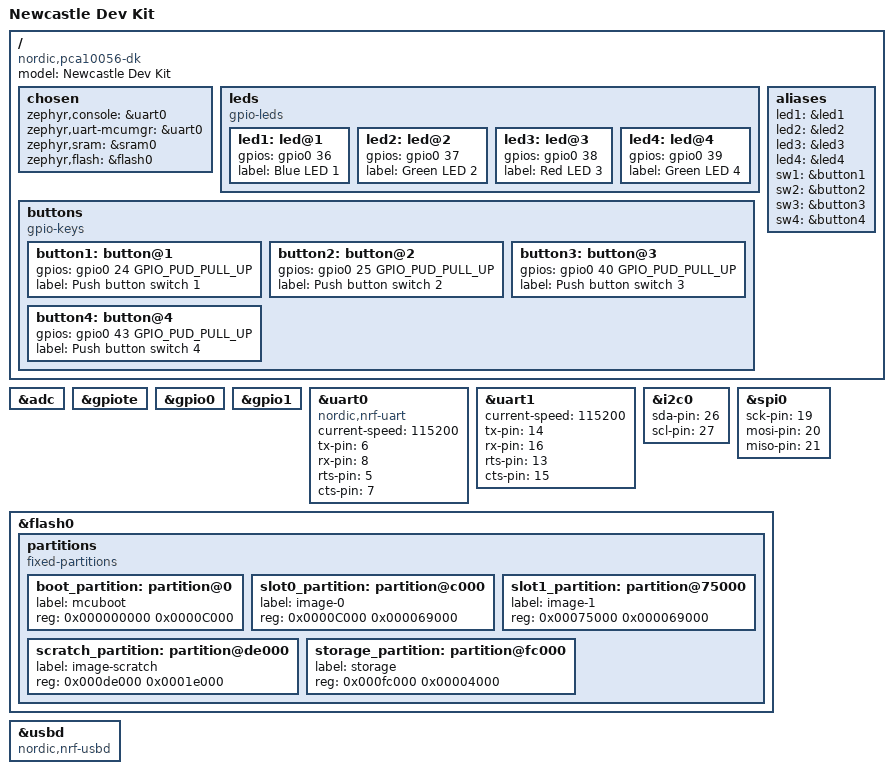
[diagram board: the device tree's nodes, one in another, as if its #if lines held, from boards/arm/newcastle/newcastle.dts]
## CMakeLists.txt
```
cmake_minimum_required(VERSION 3.8.2)
set(BOARD_ROOT ${CMAKE_CURRENT_LIST_DIR})
set(BOARD newcastle)
include($ENV{ZEPHYR_BASE}/cmake/app/boilerplate.cmake NO_POLICY_SCOPE)
project(Cellular_IOT)

target_sources(app PRIVATE
  src/main.c
  src/hrs.c
  src/dis.c
  src/bas.c
  src/cts.c
  src/app_bt.c
  src/app_led.c
  src/console_rx.c
  src/hl7800.c
)

zephyr_library_include_directories($ENV{ZEPHYR_BASE}/samples/bluetooth)
```

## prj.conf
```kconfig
CONFIG_BT_DEBUG_LOG=y
CONFIG_BT_SMP=y
CONFIG_BT_SIGNING=y
CONFIG_BT_PERIPHERAL=y
CONFIG_BT_ATT_PREPARE_COUNT=2
CONFIG_BT_PRIVACY=y
CONFIG_BT_DEVICE_NAME="Newcastle"
CONFIG_BT_DEVICE_APPEARANCE=833
CONFIG_DEBUG_OPTIMIZATIONS=y
CONFIG_UART_INTERRUPT_DRIVEN=y
CONFIG_CONSOLE_SUBSYS=y
CONFIG_CONSOLE_GETLINE=y
CONFIG_NO_OPTIMIZATIONS=y
CONFIG_DEBUG=y
```

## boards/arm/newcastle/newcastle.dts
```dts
/*
 * Copyright (c) 2017 Linaro Limited
 *
 * SPDX-License-Identifier: Apache-2.0
 */

/dts-v1/;
#include <nordic/nrf52840_qiaa.dtsi>

/ {
	model = "Newcastle Dev Kit";
	compatible = "nordic,pca10056-dk", "nordic,nrf52840-qiaa",
		     "nordic,nrf52840";

	chosen {
		zephyr,console = &uart0;
#ifdef CONFIG_MCUMGR_SMP_UART
		zephyr,uart-mcumgr = &uart0;
#endif
		zephyr,sram = &sram0;
		zephyr,flash = &flash0;
	};

	leds {
		compatible = "gpio-leds";
		led1: led@1 {
			gpios = <&gpio0 36 GPIO_INT_ACTIVE_HIGH>;
			label = "Blue LED 1";
		};
		led2: led@2 {
			gpios = <&gpio0 37 GPIO_INT_ACTIVE_HIGH>;
			label = "Green LED 2";
		};
		led3: led@3 {
			gpios = <&gpio0 38 GPIO_INT_ACTIVE_HIGH>;
			label = "Red LED 3";
		};
		led4: led@4 {
			gpios = <&gpio0 39 GPIO_INT_ACTIVE_HIGH>;
			label = "Green LED 4";
		};
	};

	buttons {
		compatible = "gpio-keys";
		button1: button@1 {
			gpios = <&gpio0 24 GPIO_PUD_PULL_UP>;
			label = "Push button switch 1";
		};
		button2: button@2 {
			gpios = <&gpio0 25 GPIO_PUD_PULL_UP>;
			label = "Push button switch 2";
		};
		button3: button@3 {
			gpios = <&gpio0 40 GPIO_PUD_PULL_UP>;
			label = "Push button switch 3";
		};
		button4: button@4 {
			gpios = <&gpio0 43 GPIO_PUD_PULL_UP>;
			label = "Push button switch 4";
		};
	};

	/* These aliases are provided for compatibility with samples */
	aliases {
		led1 = &led1;
		led2 = &led2;
		led3 = &led3;
		led4 = &led4;
		sw1 = &button1;
		sw2 = &button2;
		sw3 = &button3;
		sw4 = &button4;
	};
};

&adc {
	status ="ok";
};

&gpiote {
	status ="ok";
};

&gpio0 {
	status ="ok";
};

&gpio1 {
	status ="ok";
};

&uart0 {
	compatible = "nordic,nrf-uart";
	current-speed = <115200>;
	status = "ok";
	tx-pin = <6>;
	rx-pin = <8>;
	rts-pin = <5>;
	cts-pin = <7>;
};

#ifdef CONFIG_UART_1_NRF_UARTE
&uart1 {
	current-speed = <115200>;
	status = "ok";
	tx-pin = <14>;
	rx-pin = <16>;
	rts-pin = <13>;
	cts-pin = <15>;
/*
#ifdef CONFIG_MODEM_WNCM14A2A
	wncm14a2a {
		compatible = "wnc,m14a2a";
		label = "wncm14a2a";
		mdm-boot-mode-sel-gpios = <&gpio1 2 0>;
		mdm-power-gpios = <&gpio1 3 0>;
		mdm-keep-awake-gpios = <&gpio1 7 0>;
		mdm-reset-gpios = <&gpio1 10 0>;
		mdm-shld-trans-ena-gpios = <&gpio1 11 0>;
		status = "ok";
	};
#endif
*/
};
#endif

&i2c0 {
	status = "ok";
	sda-pin = <26>;
	scl-pin = <27>;
};

/*
&i2c1 {
	status = "ok";
	sda-pin = <30>;
	scl-pin = <31>;
};
*/

&spi0 {
	status = "ok";
	sck-pin = <19>;
	mosi-pin = <20>;
	miso-pin = <21>;
};

/*
&spi1 {
	status = "ok";
	sck-pin = <31>;
	mosi-pin = <30>;
	miso-pin = <40>;
};

&spi2 {
	status = "ok";
	sck-pin = <43>;
	mosi-pin = <44>;
	miso-pin = <45>;
};

&spi3 {
	status = "ok";
	sck-pin = <42>;
	mosi-pin = <41>;
	miso-pin = <20>;
};
*/

&flash0 {
	/*
	 * For more information, see:
	 * http://docs.zephyrproject.org/devices/dts/flash_partitions.html
	 */
	partitions {
		compatible = "fixed-partitions";
		#address-cells = <1>;
		#size-cells = <1>;

		boot_partition: partition@0 {
			label = "mcuboot";
			reg = <0x000000000 0x0000C000>;
		};
		slot0_partition: partition@c000 {
			label = "image-0";
			reg = <0x0000C000 0x000069000>;
		};
		slot1_partition: partition@75000 {
			label = "image-1";
			reg = <0x00075000 0x000069000>;
		};
		scratch_partition: partition@de000 {
			label = "image-scratch";
			reg = <0x000de000 0x0001e000>;
		};

#if defined(CONFIG_FS_FLASH_MAP_STORAGE)
		storage_partition: partition@fc000 {
			label = "storage";
			reg = <0x000fc000 0x00004000>;
		};
#endif
	};
};

&usbd {
	compatible = "nordic,nrf-usbd";
	status = "ok";
};
```

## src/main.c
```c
/* main.c - Application main entry point */

#include <zephyr.h>
#include <misc/printk.h>

#include "app_led.h"


void main(void)
{
    printk("Newcastle Test App\nSystem up time %d us\n", SYS_CLOCK_HW_CYCLES_TO_NS(k_cycle_get_32())/1000);
    led_init();

    while (1)
    {
        // TODO: LED heartbeat should use a timer instead of relying on the thread loop.
        // TODO: wait in main thread on event (semaphore) until some work needs to be done.
        ledHeartBeat();
        k_sleep(MSEC_PER_SEC);
        //printk("Heartbeat!\n");
    }
}
```

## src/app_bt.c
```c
#include <bluetooth/bluetooth.h>
#include <bluetooth/hci.h>
#include <bluetooth/conn.h>
#include <bluetooth/uuid.h>
#include <bluetooth/gatt.h>

#include <gatt/hrs.h>
#include <gatt/dis.h>
#include <gatt/bas.h>
#include <gatt/cts.h>

#include <settings/settings.h>

#include <gpio.h>

#include "app_bt.h"

/* ********** DEFINES ********** */
#define DEVICE_NAME CONFIG_BT_DEVICE_NAME
#define DEVICE_NAME_LEN (sizeof(DEVICE_NAME) - 1)
#define MAX_DATA 74

#ifdef SW0_GPIO_INT_CONF
#define EDGE SW0_GPIO_INT_CONF
#else
/*
 * If SW0_GPIO_INT_CONF not defined used default EDGE value.
 * Change this to use a different interrupt trigger
 */
#define EDGE (GPIO_INT_EDGE | GPIO_INT_ACTIVE_LOW)
#endif

/* ********** FUNCTION DEFINITIONS ********** */
static ssize_t read_vnd(struct bt_conn *conn, const struct bt_gatt_attr *attr,
                        void *buf, u16_t len, u16_t offset);
static ssize_t write_vnd(struct bt_conn *conn, const struct bt_gatt_attr *attr,
                         const void *buf, u16_t len, u16_t offset,
                         u8_t flags);
static void vnd_ccc_cfg_changed(const struct bt_gatt_attr *attr, u16_t value);
static void indicate_cb(struct bt_conn *conn, const struct bt_gatt_attr *attr,
                        u8_t err);
static ssize_t read_long_vnd(struct bt_conn *conn,
                             const struct bt_gatt_attr *attr, void *buf,
                             u16_t len, u16_t offset);
static ssize_t write_long_vnd(struct bt_conn *conn,
                              const struct bt_gatt_attr *attr, const void *buf,
                              u16_t len, u16_t offset, u8_t flags);
static ssize_t read_signed(struct bt_conn *conn, const struct bt_gatt_attr *attr,
                           void *buf, u16_t len, u16_t offset);
static ssize_t write_signed(struct bt_conn *conn, const struct bt_gatt_attr *attr,
                            const void *buf, u16_t len, u16_t offset,
                            u8_t flags);
static void connected(struct bt_conn *conn, u8_t err);
static void disconnected(struct bt_conn *conn, u8_t reason);
static void bt_ready(int err);
static void auth_passkey_display(struct bt_conn *conn, unsigned int passkey);
static void auth_cancel(struct bt_conn *conn);
static void advertButtonInit();
void advertButtonPressed(struct device *gpiob, struct gpio_callback *cb,
                         u32_t pins);
static void advertLedInit();
static void flashAdvertLed();

/* Custom Service Variables */
static struct bt_uuid_128 vnd_uuid = BT_UUID_INIT_128(
    0xf0, 0xde, 0xbc, 0x9a, 0x78, 0x56, 0x34, 0x12,
    0x78, 0x56, 0x34, 0x12, 0x78, 0x56, 0x34, 0x12);

static struct bt_uuid_128 vnd_enc_uuid = BT_UUID_INIT_128(
    0xf1, 0xde, 0xbc, 0x9a, 0x78, 0x56, 0x34, 0x12,
    0x78, 0x56, 0x34, 0x12, 0x78, 0x56, 0x34, 0x12);

static struct bt_uuid_128 vnd_auth_uuid = BT_UUID_INIT_128(
    0xf2, 0xde, 0xbc, 0x9a, 0x78, 0x56, 0x34, 0x12,
    0x78, 0x56, 0x34, 0x12, 0x78, 0x56, 0x34, 0x12);

static u8_t vnd_value[] = {'V', 'e', 'n', 'd', 'o', 'r'};
static struct bt_gatt_ccc_cfg vnd_ccc_cfg[BT_GATT_CCC_MAX] = {};
static u8_t simulate_vnd;
static u8_t indicating;
static struct bt_gatt_indicate_params ind_params;
static int signed_value;

static u8_t vnd_long_value[] = {
    'V', 'e', 'n', 'd', 'o', 'r', ' ', 'd', 'a', 't', 'a', '1',
    'V', 'e', 'n', 'd', 'o', 'r', ' ', 'd', 'a', 't', 'a', '2',
    'V', 'e', 'n', 'd', 'o', 'r', ' ', 'd', 'a', 't', 'a', '3',
    'V', 'e', 'n', 'd', 'o', 'r', ' ', 'd', 'a', 't', 'a', '4',
    'V', 'e', 'n', 'd', 'o', 'r', ' ', 'd', 'a', 't', 'a', '5',
    'V', 'e', 'n', 'd', 'o', 'r', ' ', 'd', 'a', 't', 'a', '6',
    '.', ' '};

static const struct bt_uuid_128 vnd_long_uuid = BT_UUID_INIT_128(
    0xf3, 0xde, 0xbc, 0x9a, 0x78, 0x56, 0x34, 0x12,
    0x78, 0x56, 0x34, 0x12, 0x78, 0x56, 0x34, 0x12);

static struct bt_gatt_cep vnd_long_cep = {
    .properties = BT_GATT_CEP_RELIABLE_WRITE,
};

static const struct bt_uuid_128 vnd_signed_uuid = BT_UUID_INIT_128(
    0xf3, 0xde, 0xbc, 0x9a, 0x78, 0x56, 0x34, 0x13,
    0x78, 0x56, 0x34, 0x12, 0x78, 0x56, 0x34, 0x13);

/* Vendor Primary Service Declaration */
static struct bt_gatt_attr vnd_attrs[] = {
    /* Vendor Primary Service Declaration */
    BT_GATT_PRIMARY_SERVICE(&vnd_uuid),
    BT_GATT_CHARACTERISTIC(&vnd_enc_uuid.uuid,
                           BT_GATT_CHRC_READ | BT_GATT_CHRC_WRITE |
                               BT_GATT_CHRC_INDICATE,
                           BT_GATT_PERM_READ_ENCRYPT |
                               BT_GATT_PERM_WRITE_ENCRYPT,
                           read_vnd, write_vnd, vnd_value),
    BT_GATT_CCC(vnd_ccc_cfg, vnd_ccc_cfg_changed),
    BT_GATT_CHARACTERISTIC(&vnd_auth_uuid.uuid,
                           BT_GATT_CHRC_READ | BT_GATT_CHRC_WRITE,
                           BT_GATT_PERM_READ_AUTHEN |
                               BT_GATT_PERM_WRITE_AUTHEN,
                           read_vnd, write_vnd, vnd_value),
    BT_GATT_CHARACTERISTIC(&vnd_long_uuid.uuid, BT_GATT_CHRC_READ | BT_GATT_CHRC_WRITE | BT_GATT_CHRC_EXT_PROP,
                           BT_GATT_PERM_READ | BT_GATT_PERM_WRITE |
                               BT_GATT_PERM_PREPARE_WRITE,
                           read_long_vnd, write_long_vnd, &vnd_long_value),
    BT_GATT_CEP(&vnd_long_cep),
    BT_GATT_CHARACTERISTIC(&vnd_signed_uuid.uuid, BT_GATT_CHRC_READ | BT_GATT_CHRC_WRITE | BT_GATT_CHRC_AUTH,
                           BT_GATT_PERM_READ | BT_GATT_PERM_WRITE,
                           read_signed, write_signed, &signed_value),
};

static struct bt_gatt_service vnd_svc = BT_GATT_SERVICE(vnd_attrs);

static const struct bt_data ad[] = {
    BT_DATA_BYTES(BT_DATA_FLAGS, (BT_LE_AD_GENERAL | BT_LE_AD_NO_BREDR)),
    BT_DATA_BYTES(BT_DATA_UUID16_ALL,
                  0x0d, 0x18, 0x0f, 0x18, 0x05, 0x18),
    BT_DATA_BYTES(BT_DATA_UUID128_ALL,
                  0xf0, 0xde, 0xbc, 0x9a, 0x78, 0x56, 0x34, 0x12,
                  0x78, 0x56, 0x34, 0x12, 0x78, 0x56, 0x34, 0x12),
};

static const struct bt_data sd[] = {
    BT_DATA(BT_DATA_NAME_COMPLETE, DEVICE_NAME, DEVICE_NAME_LEN),
};

static struct bt_conn_cb conn_callbacks = {
    .connected = connected,
    .disconnected = disconnected,
};

static struct bt_conn_auth_cb auth_cb_display = {
    .passkey_display = auth_passkey_display,
    .passkey_entry = NULL,
    .cancel = auth_cancel,
};

static struct device *advertButton_dev;
static struct device *advertLed_dev;
static struct gpio_callback gpio_cb;
static bool bAdvertising = 0;
static bool bConnected = 0;
static bool bSignalAdvertising = 0;

/* ********** FUNCTIONS ********** */
static ssize_t read_vnd(struct bt_conn *conn, const struct bt_gatt_attr *attr,
                        void *buf, u16_t len, u16_t offset)
{
    const char *value = attr->user_data;

    return bt_gatt_attr_read(conn, attr, buf, len, offset, value,
                             strlen(value));
}

static ssize_t write_vnd(struct bt_conn *conn, const struct bt_gatt_attr *attr,
                         const void *buf, u16_t len, u16_t offset,
                         u8_t flags)
{
    u8_t *value = attr->user_data;

    if (offset + len > sizeof(vnd_value))
    {
        return BT_GATT_ERR(BT_ATT_ERR_INVALID_OFFSET);
    }

    memcpy(value + offset, buf, len);

    return len;
}

static void vnd_ccc_cfg_changed(const struct bt_gatt_attr *attr, u16_t value)
{
    simulate_vnd = (value == BT_GATT_CCC_INDICATE) ? 1 : 0;
}

static void indicate_cb(struct bt_conn *conn, const struct bt_gatt_attr *attr,
                        u8_t err)
{
    printk("Indication %s\n", err != 0 ? "fail" : "success");
    indicating = 0;
}

static ssize_t read_long_vnd(struct bt_conn *conn,
                             const struct bt_gatt_attr *attr, void *buf,
                             u16_t len, u16_t offset)
{
    const char *value = attr->user_data;

    return bt_gatt_attr_read(conn, attr, buf, len, offset, value,
                             sizeof(vnd_long_value));
}

static ssize_t write_long_vnd(struct bt_conn *conn,
                              const struct bt_gatt_attr *attr, const void *buf,
                              u16_t len, u16_t offset, u8_t flags)
{
    u8_t *value = attr->user_data;

    if (flags & BT_GATT_WRITE_FLAG_PREPARE)
    {
        return 0;
    }

    if (offset + len > sizeof(vnd_long_value))
    {
        return BT_GATT_ERR(BT_ATT_ERR_INVALID_OFFSET);
    }

    memcpy(value + offset, buf, len);

    return len;
}

static ssize_t read_signed(struct bt_conn *conn, const struct bt_gatt_attr *attr,
                           void *buf, u16_t len, u16_t offset)
{
    const char *value = attr->user_data;

    return bt_gatt_attr_read(conn, attr, buf, len, offset, value,
                             sizeof(signed_value));
}

static ssize_t write_signed(struct bt_conn *conn, const struct bt_gatt_attr *attr,
                            const void *buf, u16_t len, u16_t offset,
                            u8_t flags)
{
    u8_t *value = attr->user_data;

    if (offset + len > sizeof(signed_value))
    {
        return BT_GATT_ERR(BT_ATT_ERR_INVALID_OFFSET);
    }

    memcpy(value + offset, buf, len);

    return len;
}

static void connected(struct bt_conn *conn, u8_t err)
{
    if (err)
    {
        bConnected = 0;
        printk("Connection failed (err %u)\n", err);
    }
    else
    {
        bConnected = 1;
        bAdvertising = 0;
        printk("Connected\n");
    }
}

static void disconnected(struct bt_conn *conn, u8_t reason)
{
    bConnected = 0;
    bAdvertising = 1;
    printk("Disconnected (reason %u)\n", reason);
}

static void bt_ready(int err)
{
    if (err)
    {
        printk("Bluetooth init failed (err %d)\n", err);
        return;
    }

    printk("Bluetooth initialized\n");

    hrs_init(0x01);
    bas_init();
    cts_init();
    dis_init(CONFIG_SOC, "Laird");
    bt_gatt_service_register(&vnd_svc);

    if (IS_ENABLED(CONFIG_SETTINGS))
    {
        settings_load();
    }
}

static void startAdvertising()
{
    int err = bt_le_adv_start(BT_LE_ADV_CONN, ad, ARRAY_SIZE(ad),
                              sd, ARRAY_SIZE(sd));
    if (err)
    {
        bAdvertising = 0;
        printk("Advertising failed to start (err %d)\n", err);
        return;
    }

    bAdvertising = 1;
    printk("Advertising successfully started\n");
}

static void stopAdvertising()
{
    int err = bt_le_adv_stop();
    if (err)
    {
        printk("Advertising failed to stop (err %d)\n", err);
        return;
    }

    bAdvertising = 0;
    printk("Advertising stopped\n");
}

static void auth_passkey_display(struct bt_conn *conn, unsigned int passkey)
{
    char addr[BT_ADDR_LE_STR_LEN];

    bt_addr_le_to_str(bt_conn_get_dst(conn), addr, sizeof(addr));

    printk("Passkey for %s: %06u\n", addr, passkey);
}

static void auth_cancel(struct bt_conn *conn)
{
    char addr[BT_ADDR_LE_STR_LEN];

    bt_addr_le_to_str(bt_conn_get_dst(conn), addr, sizeof(addr));

    printk("Pairing cancelled: %s\n", addr);
}

static void advertButtonInit()
{
    int ret;

    advertButton_dev = device_get_binding(SW0_GPIO_NAME);
    if (!advertButton_dev)
    {
        printk("Cannot find %s!\n", SW0_GPIO_NAME);
        return;
    }

    ret = gpio_pin_configure(advertButton_dev, ADVERT_BUTTON,
                             GPIO_DIR_IN | GPIO_INT | SW0_GPIO_PIN_PUD | EDGE);
    if (ret)
    {
        printk("Error configuring GPIO %d!\n", ADVERT_BUTTON);
    }

    gpio_init_callback(&gpio_cb, advertButtonPressed, BIT(ADVERT_BUTTON));
    ret = gpio_add_callback(advertButton_dev, &gpio_cb);
    if (ret)
    {
        printk("Error adding GPIO %d callback!\n", ADVERT_BUTTON);
    }

    ret = gpio_pin_enable_callback(advertButton_dev, ADVERT_BUTTON);
    if (ret)
    {
        printk("Error enabling GPIO %d callback!\n", ADVERT_BUTTON);
    }
}

void advertButtonPressed(struct device *gpiob, struct gpio_callback *cb,
                         u32_t pins)
{
    // Set flag to BT app thread can start advertising
    bSignalAdvertising = 1;
}

static void advertLedInit()
{
    int ret;

    advertLed_dev = device_get_binding(LED1_GPIO_PORT);
    if (!advertLed_dev)
    {
        printk("Cannot find %s!\n", LED1_GPIO_PORT);
        return;
    }

    ret = gpio_pin_configure(advertLed_dev, ADVERT_LED, (GPIO_DIR_OUT));
    if (ret)
    {
        printk("Error configuring GPIO %d!\n", ADVERT_LED);
    }

    ret = gpio_pin_write(advertLed_dev, ADVERT_LED, LED_OFF);
    if (ret)
    {
        printk("Error setting GPIO %d!\n", ADVERT_LED);
    }
}

static void flashAdvertLed()
{
    int ret;
    ret = gpio_pin_write(advertLed_dev, ADVERT_LED, LED_ON);
    if (ret)
    {
        printk("Error setting GPIO %d!\n", ADVERT_LED);
    }
    k_sleep(25);
    ret = gpio_pin_write(advertLed_dev, ADVERT_LED, LED_OFF);
    if (ret)
    {
        printk("Error setting GPIO %d!\n", ADVERT_LED);
    }
}

void app_bt_thread()
{
    int err;

    err = bt_enable(bt_ready);
    if (err)
    {
        printk("Bluetooth init failed (err %d)\n", err);
        return;
    }

    bt_conn_cb_register(&conn_callbacks);
    bt_conn_auth_cb_register(&auth_cb_display);

    advertLedInit();
    advertButtonInit();

    while (1)
    {
        k_sleep(MSEC_PER_SEC);

        if (bSignalAdvertising)
        {
            bSignalAdvertising = 0;
            if (!bAdvertising && !bConnected)
            {
                startAdvertising();
            }
            else if (bAdvertising)
            {
                stopAdvertising();
            }
        }

        if (bAdvertising)
        {
            flashAdvertLed();
        }

        /* Current Time Service updates only when time is changed */
        cts_notify();

        /* Heartrate measurements simulation */
        hrs_notify();

        /* Battery level simulation */
        bas_notify();

        /* Vendor indication simulation */
        if (simulate_vnd)
        {
            if (indicating)
            {
                continue;
            }

            ind_params.attr = &vnd_attrs[2];
            ind_params.func = indicate_cb;
            ind_params.data = &indicating;
            ind_params.len = sizeof(indicating);

            if (bt_gatt_indicate(NULL, &ind_params) == 0)
            {
                indicating = 1;
            }
        }
    }
}

K_THREAD_DEFINE(app_bt_id, 512, app_bt_thread, NULL, NULL, NULL,
                7, 0, K_NO_WAIT);
```

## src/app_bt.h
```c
#ifndef APP_BT_H
#define APP_BT_H

#include <board.h>

#define ADVERT_BUTTON_PORT      SW1_GPIO_CONTROLLER
#define ADVERT_BUTTON           SW1_GPIO_PIN
#define ADVERT_LED_PORT         LED2_GPIO_CONTROLLER
#define ADVERT_LED              LED2_GPIO_PIN
#define LED_OFF     0
#define LED_ON      1

void app_bt_thread();

#endif
```

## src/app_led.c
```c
#include "app_led.h"

#include <gpio.h>

static struct device *gpio_dev;

void led_init(void)
{
    int ret;

    gpio_dev = device_get_binding(HEARTBEAT_LED_PORT);
    if (!gpio_dev)
    {
        printk("Cannot find %s!\n", HEARTBEAT_LED_PORT);
        return;
    }

    ret = gpio_pin_configure(gpio_dev, HEARTBEAT_LED, (GPIO_DIR_OUT));
    if (ret)
    {
        printk("Error configuring GPIO %d!\n", HEARTBEAT_LED);
    }

    ret = gpio_pin_write(gpio_dev, HEARTBEAT_LED, LED_OFF);
    if (ret)
    {
        printk("Error setting GPIO %d!\n", HEARTBEAT_LED);
    }
}

void ledHeartBeat(void)
{
    int ret;
    /* flash LED twice quickly */
    for (u8_t i = 0; i < 2; i++)
    {
        ret = gpio_pin_write(gpio_dev, HEARTBEAT_LED, LED_ON);
        if (ret)
        {
            printk("Error setting GPIO %d!\n", HEARTBEAT_LED);
        }
        k_sleep(25);
        ret = gpio_pin_write(gpio_dev, HEARTBEAT_LED, LED_OFF);
        if (ret)
        {
            printk("Error setting GPIO %d!\n", HEARTBEAT_LED);
        }
        k_sleep(50);
    }
}
```

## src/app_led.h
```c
#ifndef APP_LED_H
#define APP_LED_H

#include <board.h>

#define LED_OFF 1
#define LED_ON 0
#define HEARTBEAT_LED LED0_GPIO_PIN


/**
 *  Init the LEDs for the board
 */
void led_init(void);

/**
 * This will flash the heart beat LED twice.
 * This function will block for the amount of time it takes to flash the LED
 */
void ledHeartBeat(void);

#endif
```

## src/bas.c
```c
/* Workaround build system bug that will put objects in source dir */
#include "../../zephyr/samples/bluetooth/gatt/bas.c"
```

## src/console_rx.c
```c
#include <string.h>
#include <zephyr.h>
#include <misc/printk.h>
#include <console.h>

#include "console_rx.h"
#include "hl7800.h"

static void process_cmd(char *cmdStr);
static void parse_cmd(char *cmdStr);
static void console_rx_thread();

static void process_cmd(char *cmdStr)
{
    int len = strlen(cmdStr);
    if (len == 0)
    {
        printk(CMD_RESP_OK);
    }
    else
    {
        parse_cmd(cmdStr);
    }
}

static void parse_cmd(char *cmdStr)
{
    int len = strlen(cmdStr);
    if (len == 1)
    {
        switch (cmdStr[0])
        {
        case CMD_R:
            toggleLteReset();
            break;
        case CMD_W:
            toggleLteWake();
            break;
        default:
            printk("Unknown cmd \"%s\"\n", cmdStr);
            break;
        }
    }
    else
    {
        char sendCmd[len];
        memset(sendCmd, 0, sizeof(sendCmd));
        switch (cmdStr[0])
        {
        case CMD_S:
            // strip s
            strncpy(sendCmd, cmdStr + 1, len - 1);
            // add cmd ending
            strcat(sendCmd, "\r");
            sendLteCmd(sendCmd);
            break;
        default:
            printk("Unknown cmd \"%s\"\n", cmdStr);
            break;
        }
    }
}

static void console_rx_thread()
{
    console_getline_init();

    while (1)
    {
        char *s = console_getline();
        process_cmd(s);
    }
}

K_THREAD_DEFINE(console_rx, 512, console_rx_thread, NULL, NULL, NULL,
                7, 0, K_NO_WAIT);
```

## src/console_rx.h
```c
#ifndef CONSOLE_RX_H
#define CONSOLE_RX_H

#define MAX_CMD_SIZE    256

#define CMD_R           'r'
#define CMD_W           'w'
#define CMD_S           's'

#define CMD_RESP_OK          "OK\n"

#endif
```

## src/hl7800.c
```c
#include <zephyr.h>
#include <misc/printk.h>
#include <string.h>
#include <gpio.h>
#include <uart.h>

#include "hl7800.h"

static struct device *gpio1_dev;
static struct device *lte_uart_dev;

static int lteResetState = 0;
static int lteWakeState = 0;
static u8_t lte_uart_rx_buf[LTE_UART_RX_READ_SIZE];
static u8_t lte_rx_msg_buf[LTE_UART_RX_PIPE_SIZE];
static char lte_temp_msg[LTE_UART_RX_PIPE_SIZE];
static int lte_tmp_msg_index = 0;
static int parseCmdState = CMD_STATE_FIND_MSG_START_1;
static bool lteBooted = false;

K_PIPE_DEFINE(lte_rx_pipe, LTE_UART_RX_PIPE_SIZE, 1);
K_SEM_DEFINE(lte_rx_sem, 0, 1);
K_SEM_DEFINE(lte_boot_sem, 0, 1);
K_SEM_DEFINE(lte_event_sem, 0, 1);
K_SEM_DEFINE(lte_rx_cmd_sem, 0, 1);

static void initIO();
static void lteUartInit();
static void lte_uart_isr(struct device *dev);
void toggleLteReset();
void toggleLteWake();
static void process_lte_rx();
static void parse_lte_cmd(u8_t *msg, int size);
static void start_lte_rx_timer();
static void stop_lte_rx_timer();
static void start_lte_boot_timer();
static void stop_lte_boot_timer();
static void lte_rx_timer_handler(struct k_timer *timer_id);
static void lte_boot_timer_handler(struct k_timer *timer_id);
void sendLteCmd(char *cmd);
void waitForLteCmdResponse();
static void queryLteInfo();
static void hl7800_thread();
static void hl7800_rx_thread();

K_TIMER_DEFINE(lte_rx_timer, lte_rx_timer_handler, NULL);
K_TIMER_DEFINE(lte_boot_timer, lte_boot_timer_handler, NULL);

K_THREAD_DEFINE(hl7800rx, 512, hl7800_rx_thread, NULL, NULL, NULL,
                7, 0, K_NO_WAIT);

K_THREAD_DEFINE(hl7800, 512, hl7800_thread, NULL, NULL, NULL,
                7, 0, K_NO_WAIT);

// init the control IO for the HL7800
static void initIO()
{
    int ret;

    // Open the GPIO1 device
    gpio1_dev = device_get_binding(SIO_LTE_IO_CONTROLLER);
    if (!gpio1_dev)
    {
        printk("Cannot find %s!\n", SIO_LTE_IO_CONTROLLER);
        return;
    }

    // LTE reset
    ret = gpio_pin_configure(gpio1_dev, SIO_LTE_RESET, (GPIO_DIR_OUT | GPIO_DS_DISCONNECT_HIGH));
    if (ret)
    {
        printk("Error configuring GPIO %d!\n", ret);
    }
    lteResetState = 1;
    ret = gpio_pin_write(gpio1_dev, SIO_LTE_RESET, lteResetState);
    if (ret)
    {
        printk("Error setting GPIO %d!\n", ret);
    }
    toggleLteReset();
    toggleLteReset();

    // LTE wake
    ret = gpio_pin_configure(gpio1_dev, SIO_LTE_WAKE, GPIO_DIR_OUT);
    if (ret)
    {
        printk("Error configuring GPIO %d!\n", ret);
    }
    lteWakeState = 1;
    ret = gpio_pin_write(gpio1_dev, SIO_LTE_WAKE, lteWakeState);
    if (ret)
    {
        printk("Error setting GPIO %d!\n", ret);
    }

    // LTE pwr on
    ret = gpio_pin_configure(gpio1_dev, SIO_LTE_POWER_ON, (GPIO_DIR_OUT | GPIO_DS_DISCONNECT_HIGH));
    if (ret)
    {
        printk("Error configuring GPIO %d!\n", ret);
    }
    ret = gpio_pin_write(gpio1_dev, SIO_LTE_POWER_ON, 1);
    if (ret)
    {
        printk("Error setting GPIO %d!\n", ret);
    }

    // LTE fast shutdown
    ret = gpio_pin_configure(gpio1_dev, SIO_LTE_FAST_SHUTD, (GPIO_DIR_OUT | GPIO_DS_DISCONNECT_HIGH));
    if (ret)
    {
        printk("Error configuring GPIO %d!\n", ret);
    }
    ret = gpio_pin_write(gpio1_dev, SIO_LTE_FAST_SHUTD, 1);
    if (ret)
    {
        printk("Error setting GPIO %d!\n", ret);
    }

    // LTE gps enable
    ret = gpio_pin_configure(gpio1_dev, SIO_LTE_GPS_EN, (GPIO_DIR_OUT | GPIO_DS_DISCONNECT_HIGH));
    if (ret)
    {
        printk("Error configuring GPIO %d!\n", ret);
    }
    ret = gpio_pin_write(gpio1_dev, SIO_LTE_GPS_EN, 0);
    if (ret)
    {
        printk("Error setting GPIO %d!\n", ret);
    }

    // LTE TX on
    ret = gpio_pin_configure(gpio1_dev, SIO_LTE_TX_ON, GPIO_DIR_IN);
    if (ret)
    {
        printk("Error configuring GPIO %d!\n", ret);
    }
}

static void lteUartInit()
{
    lte_uart_dev = device_get_binding(LTE_UART_DEV);
    if (lte_uart_dev == NULL)
    {
        printk("Error opening LTE UART\n");
        return;
    }

    uart_irq_callback_set(lte_uart_dev, lte_uart_isr);
    uart_irq_rx_enable(lte_uart_dev);
}

static void lte_uart_isr(struct device *dev)
{
    int len, ret;
    size_t bytes_written;

    /* Verify uart_irq_update() */
    if (!uart_irq_update(dev))
    {
        printk("retval should always be 1\n");
        return;
    }

    while (uart_irq_update(dev) &&
           uart_irq_rx_ready(dev))
    {
        len = uart_fifo_read(lte_uart_dev, lte_uart_rx_buf, sizeof(lte_uart_rx_buf));

        if (len > 0)
        {
            //printk("Bytes read: %d, msg: %s\n", len, lte_uart_rx_buf);
            ret = k_pipe_put(&lte_rx_pipe,
                             lte_uart_rx_buf,
                             len, &bytes_written,
                             len, K_NO_WAIT);
            if (ret < 0)
            {
                printk("UART pip write error %d\n", ret);
            }
            else
            {
                //printk("%d bytes read; %d bytes added to pipe; bytes: %s\n", len, bytes_written, lte_uart_rx_buf);
                k_sem_give(&lte_rx_sem);
                // printk("Give semaphore\n");
            }
        }
    }
}

void toggleLteReset()
{
    int ret;

    if (lteResetState)
    {
        // set it low
        ret = gpio_pin_write(gpio1_dev, SIO_LTE_RESET, 0);
        printk("LTE reset is low\n");
        lteResetState = 0;
        lteBooted = false;
        stop_lte_boot_timer();
    }
    else
    {
        // set it high
        ret = gpio_pin_write(gpio1_dev, SIO_LTE_RESET, 1);
        printk("LTE reset is high\n");
        lteResetState = 1;
        start_lte_boot_timer();
    }
}

void toggleLteWake()
{
    int ret;

    if (lteWakeState)
    {
        // set it low
        ret = gpio_pin_write(gpio1_dev, SIO_LTE_WAKE, 0);
        printk("LTE wake is low\n");
        lteWakeState = 0;
    }
    else
    {
        // set it high
        ret = gpio_pin_write(gpio1_dev, SIO_LTE_WAKE, 1);
        printk("LTE wake is high\n");
        lteWakeState = 1;
    }
}

static void process_lte_rx()
{
    int rc;
    size_t bytesRead;

    rc = k_sem_take(&lte_rx_sem, K_FOREVER);
    rc = k_pipe_get(&lte_rx_pipe,
                    lte_rx_msg_buf,
                    sizeof(lte_rx_msg_buf),
                    &bytesRead, 1, K_NO_WAIT);
    if (rc >= 0)
    {
        parse_lte_cmd(lte_rx_msg_buf, bytesRead);
    }
}

static void parse_lte_cmd(u8_t *msg, int size)
{
    int index = 0;
    // char okStr[5];
    // char errStr[8];
    int cpySize = 0;
    //printk("LTE msg: %s\n", msg);

    do
    {
        switch (parseCmdState)
        {
        case CMD_STATE_FIND_MSG_START_1:
            lte_tmp_msg_index = 0;
            memset(lte_temp_msg, 0, sizeof(lte_temp_msg));
            if (msg[index] == '\r')
            {
                lte_temp_msg[lte_tmp_msg_index++] = msg[index++];
                parseCmdState = CMD_STATE_FIND_MSG_START_2;
                start_lte_rx_timer();
            }
            else
            {
                // Throw the byte away
                index++;
            }
            break;
        case CMD_STATE_FIND_MSG_START_2:
            if (msg[index] == '\n')
            {
                lte_temp_msg[lte_tmp_msg_index++] = msg[index++];
                parseCmdState = CMD_STATE_GET_REST;
            }
            else
            {
                stop_lte_rx_timer();
                parseCmdState = CMD_STATE_FIND_MSG_START_1;
            }
            break;
        case CMD_STATE_GET_REST:
            // if (size >= 4 && msg[index] == 'O')
            // {
            //     parseCmdState = CMD_STATE_GET_OK;
            // }
            // else if (size >= 7 && msg[index] == 'E')
            // {
            //     parseCmdState = CMD_STATE_GET_ERROR;
            // }
            // else if (size >= 10 &&
            //          msg[index] == '+' &&
            //          msg[index + 1] == 'C' &&
            //          msg[index + 2] == 'M' &&
            //          msg[index + 3] == 'E')
            // {
            //     parseCmdState = CMD_STATE_GET_EXT_ERROR;
            // }
            // else
            {
                // Continue receiving message
                stop_lte_rx_timer();
                cpySize = size - index;
                strncpy(&lte_temp_msg[lte_tmp_msg_index], &msg[index], cpySize);
                lte_tmp_msg_index += cpySize;
                index += cpySize;
                start_lte_rx_timer();
            }
            break;
            // case CMD_STATE_GET_OK:
            //     strncpy(okStr, &msg[index], sizeof(okStr) - 1);
            //     if (strcmp(okStr, "OK\r\n") == 0)
            //     {
            //         stop_lte_rx_timer();
            //         strcpy(&lte_temp_msg[lte_tmp_msg_index], okStr);
            //         index += 4;
            //         // Print the complete message
            //         printk("LTE msg: %s\n", lte_temp_msg);
            //         parseCmdState = CMD_STATE_FIND_MSG_START_1;
            //     }
            //     else
            //     {
            //         parseCmdState = CMD_STATE_GET_REST;
            //     }
            //     break;
            // case CMD_STATE_GET_ERROR:
            //     strncpy(errStr, &msg[index], sizeof(errStr) - 1);
            //     if (strcmp(errStr, "ERROR\r\n") == 0)
            //     {
            //         stop_lte_rx_timer();
            //         strcpy(&lte_temp_msg[lte_tmp_msg_index], errStr);
            //         index += 7;
            //         // Print the complete message
            //         printk("LTE msg: %s\n", lte_temp_msg);
            //         parseCmdState = CMD_STATE_FIND_MSG_START_1;
            //     }
            //     else
            //     {
            //         parseCmdState = CMD_STATE_GET_REST;
            //     }
            //     break;
            // case CMD_STATE_GET_EXT_ERROR:
            //     stop_lte_rx_timer();
            //     parseCmdState = CMD_STATE_FIND_MSG_START_1;
            //     break;
        };
    } while (index < size);
}

static void start_lte_rx_timer()
{
    k_timer_start(&lte_rx_timer, K_MSEC(LTE_UART_RX_TIMEOUT), 0);
}

static void stop_lte_rx_timer()
{
    k_timer_stop(&lte_rx_timer);
}

static void start_lte_boot_timer()
{
    k_timer_start(&lte_boot_timer, K_SECONDS(LTE_BOOT_TIME), 0);
}

static void stop_lte_boot_timer()
{
    k_timer_stop(&lte_boot_timer);
}

static void lte_rx_timer_handler(struct k_timer *timer_id)
{
    if (strlen(lte_temp_msg) > 0)
    {
        k_sem_give(&lte_rx_cmd_sem);
        printk("LTE msg: %s", lte_temp_msg);
    }
    parseCmdState = CMD_STATE_FIND_MSG_START_1;
}

static void lte_boot_timer_handler(struct k_timer *timer_id)
{
    k_sem_give(&lte_boot_sem);
    lteBooted = true;
}

void sendLteCmd(char *cmd)
{
    if (!lteBooted)
    {
        printk("LTE must be booted to send a message.\n");
        return;
    }

    if (!lteWakeState)
    {
        printk("LTE wake must be high to send a message.\n");
        return;
    }

    int len = strlen(cmd);
    if (len > 0)
    {
        printk("Send LTE msg: %s", cmd);
        k_sem_reset(&lte_rx_cmd_sem);
        for (int i = 0; i < len; i++)
        {
            uart_poll_out(lte_uart_dev, cmd[i]);
        }
    }
}

void waitForLteCmdResponse()
{
    k_sem_take(&lte_rx_cmd_sem, K_MSEC(5000));
}

static void queryLteInfo()
{
    sendLteCmd("ati9\r");
    waitForLteCmdResponse();
    sendLteCmd("at+kgsn=3\r");
    waitForLteCmdResponse();
    sendLteCmd("at+cgsn\r");
    waitForLteCmdResponse();
    sendLteCmd("at+ksrep?\r");
    waitForLteCmdResponse();
    sendLteCmd("at+ksleep?\r");
    waitForLteCmdResponse();
    sendLteCmd("at+cpsms?\r");
    waitForLteCmdResponse();
    sendLteCmd("at+kbndcfg?\r");
    waitForLteCmdResponse();
}

static void hl7800_thread()
{
    initIO();
    lteUartInit();
    k_sem_take(&lte_boot_sem, K_FOREVER);
    printk("LTE booted\n");
    queryLteInfo();

    while (1)
    {
        k_sem_take(&lte_event_sem, K_FOREVER);
        printk("LTE event received, do some work.\n");
    }
}

static void hl7800_rx_thread()
{
    while (1)
    {
        process_lte_rx();
    }
}
```

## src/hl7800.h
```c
#ifndef HL7800_H
#define HL7800_H

#define SIO_LTE_IO_CONTROLLER "GPIO_1"
#define SIO_LTE_RESET 15      //M2.71
#define SIO_LTE_WAKE 13       //M2.48
#define SIO_LTE_POWER_ON 2    //M2.67
#define SIO_LTE_TX_ON 3       //M2.44
#define SIO_LTE_GPS_EN 12     //M2.46
#define SIO_LTE_FAST_SHUTD 14 //M2.50

#define LTE_UART_DEV "UART_1"
#define LTE_UART_RX_READ_SIZE 64
#define LTE_UART_RX_PIPE_SIZE 1024
#define LTE_UART_RX_TIMEOUT 100
#define LTE_BOOT_TIME 15    // time in seconds

enum LteProcessCmdStates
{
    CMD_STATE_FIND_MSG_START_1,
    CMD_STATE_FIND_MSG_START_2,
    CMD_STATE_GET_REST,
    CMD_STATE_GET_OK,
    CMD_STATE_GET_ERROR,
    CMD_STATE_GET_EXT_ERROR
};

void toggleLteReset();
void toggleLteWake();
void sendLteCmd(char *cmd);
void waitForLteCmdResponse();

#endif
```

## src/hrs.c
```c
/* Workaround build system bug that will put objects in source dir */
#include "../../zephyr/samples/bluetooth/gatt/hrs.c"
```
